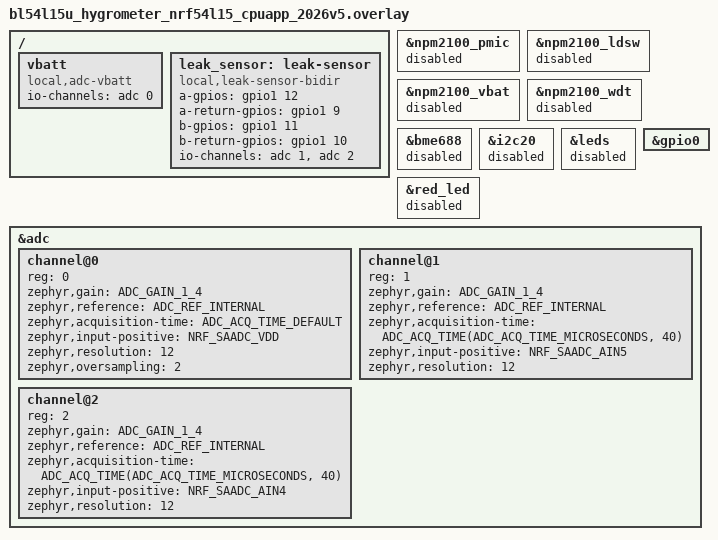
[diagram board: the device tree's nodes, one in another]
/*
 * BL54L15u Hygrometer — 2026v5 board revision (the leak sensor,
 * HW/BL54L15μ_LeakSensor)
 *
 * Differences from the base 2026v3 devicetree:
 *   - No PMIC: runs directly off a CR2 cell.
 *   - No BME688 / STCC4, single I2C bus.
 *   - No status LED.
 *   - Adds a two-way resistive leak sensor: LEAK_A=P1.12, LEAK_A_RET=P1.09,
 *     LEAK_B=P1.11, LEAK_B_RET=P1.10.
 *   - Has a buzzer on P1.05 (driven via Q1), which firmware does not drive yet.
 *     The pin is left unconfigured; R7 holds Q1 off.
 *
 * The base DTS keeps SHT4x on I2C21 (SDA=P1.14, SCL=P1.04), unchanged here.
 * Every pin this revision uses is on port 1.
 */

#include <zephyr/dt-bindings/adc/adc.h>
#include <zephyr/dt-bindings/adc/nrf-saadc.h>
#include <zephyr/dt-bindings/gpio/gpio.h>

/* ---- Remove 2026v3-only hardware ---- */

/* No nPM2100 PMIC on v5. Disable the PMIC and each of its child devices
 * individually — a node's own status is not inherited from its parent, so the
 * regulator/vbat/watchdog children would otherwise still report "okay" and the
 * firmware would pick the PMIC battery path instead of the SAADC one. */
&npm2100_pmic {
	status = "disabled";
};

&npm2100_ldsw {
	status = "disabled";
};

&npm2100_vbat {
	status = "disabled";
};

&npm2100_wdt {
	status = "disabled";
};

/* No BME688 / STCC4 and no I2C20 bus on v5 */
&bme688 {
	status = "disabled";
};

&i2c20 {
	status = "disabled";
};

/* No status LED on v5. Disable the child too (status is not inherited) so the
 * boot_led alias resolves as not-okay and the boot-LED code is skipped. */
&leds {
	status = "disabled";
};

&red_led {
	status = "disabled";
};

/* ---- Add 2026v5 hardware ---- */

/* No pin on port 0 is used. It is enabled because the Matter build links NCS's
 * DK buttons/LEDs library, which refers to the gpio0 device unconditionally and
 * does not compile without it. gpio2 stays disabled. */
&gpio0 {
	status = "okay";
};

/* SAADC: CR2 battery-voltage measurement (channel@0, internal VDD) and one
 * channel on each leak contact's pin (see leak-sensor below). */
&adc {
	status = "okay";
	#address-cells = <1>;
	#size-cells = <0>;

	/* Measure the chip supply (== CR2 voltage). The nRF54L internal reference
	 * is 0.9 V, so 1/4 gain gives a 3.6 V full scale, covering a fresh CR2
	 * (~3.2 V). adc_raw_to_millivolts_dt() does the raw->mV conversion. */
	channel@0 {
		reg = <0>;
		zephyr,gain = "ADC_GAIN_1_4";
		zephyr,reference = "ADC_REF_INTERNAL";
		zephyr,acquisition-time = <ADC_ACQ_TIME_DEFAULT>;
		zephyr,input-positive = <NRF_SAADC_VDD>;
		zephyr,resolution = <12>;
		/* 2^2 = 4x oversampling. The CR2 curve is quite flat; average in
		 * hardware to keep the reported percentage stable. */
		zephyr,oversampling = <2>;
	};

	/* Leak contacts. Each pin is sampled while the other side drives, through
	 * the divider R_water + 20 kΩ against that pin's 1 MΩ: a source of about
	 * 0.5 to 1 MΩ, so use a long acquisition time. 1/4 gain covers the full
	 * 3.6 V range.
	 * AIN5 and AIN4 are from Ezurio's pin table and are not yet confirmed on
	 * hardware; a wrong channel reads near VDD, which looks like a leak. */
	channel@1 {
		reg = <1>;
		zephyr,gain = "ADC_GAIN_1_4";
		zephyr,reference = "ADC_REF_INTERNAL";
		zephyr,acquisition-time = <ADC_ACQ_TIME(ADC_ACQ_TIME_MICROSECONDS, 40)>;
		zephyr,input-positive = <NRF_SAADC_AIN5>;  /* P1.12 = AIN5 LEAK_A */
		zephyr,resolution = <12>;
	};

	channel@2 {
		reg = <2>;
		zephyr,gain = "ADC_GAIN_1_4";
		zephyr,reference = "ADC_REF_INTERNAL";
		zephyr,acquisition-time = <ADC_ACQ_TIME(ADC_ACQ_TIME_MICROSECONDS, 40)>;
		zephyr,input-positive = <NRF_SAADC_AIN4>;  /* P1.11 = AIN4 LEAK_B */
		zephyr,resolution = <12>;
	};
};

/ {
	/* Battery voltage source consumed by sensor_reading.cpp via ADC_DT_SPEC_GET */
	vbatt: vbatt {
		compatible = "local,adc-vbatt";
		io-channels = <&adc 0>;
	};

	/* Two-way resistive leak sensor. Each contact reaches its pin through 10 kΩ
	 * (R1, R2), and each pin has 1 MΩ (R3, R4) to a return GPIO of its own, so
	 * either side can drive while the other senses:
	 *   V_sense = V_drive * 1 MΩ / (20 kΩ + R_water + 1 MΩ).
	 * The sensing pin is read digitally for an instant wake-on-wet edge and
	 * sampled with the SAADC for the software threshold. */
	leak_sensor: leak-sensor {
		compatible = "local,leak-sensor-bidir";
		a-gpios        = <&gpio1 12 GPIO_ACTIVE_HIGH>;  /* P1.12 LEAK_A */
		a-return-gpios = <&gpio1 9 GPIO_ACTIVE_HIGH>;   /* P1.09 R3's return */
		b-gpios        = <&gpio1 11 GPIO_ACTIVE_HIGH>;  /* P1.11 LEAK_B */
		b-return-gpios = <&gpio1 10 GPIO_ACTIVE_HIGH>;  /* P1.10 R4's return */
		io-channels = <&adc 1>, <&adc 2>;
		io-channel-names = "a", "b";
	};
};
